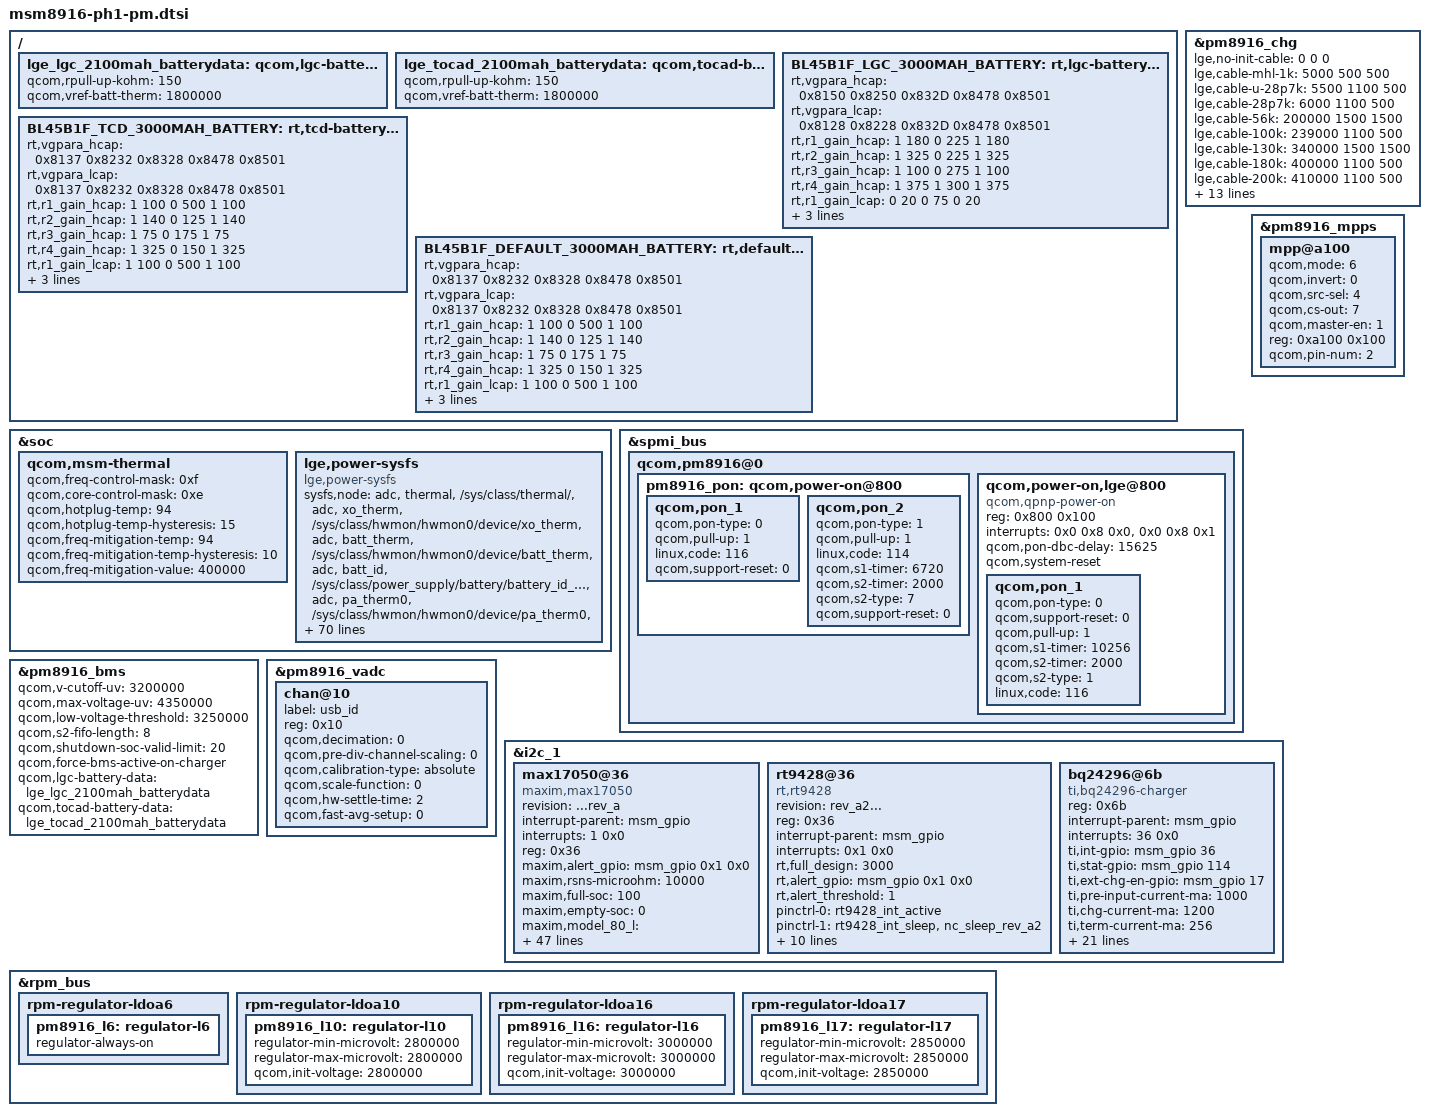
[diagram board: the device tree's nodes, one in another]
/* Copyright (c) 2012, Code Aurora Forum. All rights reserved.
 *
 * This program is free software; you can redistribute it and/or modify
* it under the terms of the GNU General Public License version 2 and
* only version 2 as published by the Free Software Foundation.
*
* This program is distributed in the hope that it will be useful,
* but WITHOUT ANY WARRANTY; without even the implied warranty of
* MERCHANTABILITY or FITNESS FOR A PARTICULAR PURPOSE.  See the
* GNU General Public License for more details.
*/

&pm8916_chg {
	status = "ok";

	lge,no-init-cable = <0 0 0>;
	lge,cable-mhl-1k = <5000 500 500>;
	lge,cable-u-28p7k = <5500 1100 500>;
	lge,cable-28p7k = <6000 1100 500>;
	lge,cable-56k = <200000 1500 1500>;
	lge,cable-100k = <239000 1100 500>;
	lge,cable-130k = <340000 1500 1500>;
	lge,cable-180k = <400000 1100 500>;
	lge,cable-200k = <410000 1100 500>;
	lge,cable-220k = <485000 1100 500>;
	lge,cable-270k = <560000 1100 500>;
	lge,cable-330k = <735000 1100 500>;
	lge,cable-620k = <955000 1100 500>;
	lge,cable-910k = <1140000 1500 1500>;
	lge,cable-none = <1900000 1100  500>;

	qcom,vddmax-mv = <4350>;
	qcom,vddsafe-mv = <4380>;
	qcom,vinmin-mv = <4470>;
	qcom,tchg-mins = <480>;
	qcom,btc-disabled;
	qcom,resume-soc = <98>;
	qcom,disable-vbatdet-based-recharge;
};

&soc {
	qcom,msm-thermal {
		qcom,freq-control-mask = <0xf>;
		qcom,core-control-mask = <0xe>;
		qcom,hotplug-temp = <94>;
		qcom,hotplug-temp-hysteresis = <15>;
		qcom,freq-mitigation-temp = <94>;
		qcom,freq-mitigation-temp-hysteresis = <10>;
		qcom,freq-mitigation-value = <400000>;
		};
};

&spmi_bus {
qcom,pm8916@0 {
		pm8916_pon: qcom,power-on@800 {
			status = "ok";
			qcom,pon_1 {
				qcom,pon-type = <0>;
				qcom,pull-up = <1>;
				linux,code = <116>;
				qcom,support-reset = <0>;
			};
			qcom,pon_2 {
				qcom,pon-type = <1>;
				qcom,pull-up = <1>;
				linux,code = <114>;
				qcom,s1-timer = <6720>;
				qcom,s2-timer = <2000>;
				qcom,s2-type = <7>;
				status = "ok";
				qcom,support-reset = <0>;
			};
		};
		qcom,power-on,lge@800 {
			compatible = "qcom,qpnp-power-on";
			reg = <0x800 0x100>;
			interrupts = <0x0 0x8 0x0>,
				     <0x0 0x8 0x1>;
			interrupt-names = "kpdpwr", "resin";
			qcom,pon-dbc-delay = <15625>;
			qcom,system-reset;
			status = "okay";
			qcom,pon_1 {
				qcom,pon-type = <0>;
				qcom,support-reset = <0>;
				qcom,pull-up = <1>;
				qcom,s1-timer = <10256>;
				qcom,s2-timer = <2000>;
				qcom,s2-type = <1>;
				linux,code = <116>;
			};
		};
	};
};

&pm8916_mpps {
	mpp@a100 {
		status = "okay";
		qcom,mode = <6>;
		qcom,invert = <0>;
		qcom,src-sel = <4>;
		qcom,cs-out = <7>;
		qcom,master-en = <1>;
		reg = <0xa100 0x100>;
		qcom,pin-num = <2>;
	};
};

/ {
	lge_lgc_2100mah_batterydata: qcom,lgc-battery-data {
		qcom,rpull-up-kohm = <150>;
		qcom,vref-batt-therm = <1800000>;

		#include "../msm8916-lge-common/batterydata_LGE_lgc_2100mAh.dtsi"
	};

	lge_tocad_2100mah_batterydata: qcom,tocad-battery-data {
		qcom,rpull-up-kohm = <150>;
		qcom,vref-batt-therm = <1800000>;

		#include "../msm8916-lge-common/batterydata_LGE_tocad_2100mAh.dtsi"
	};
};

/ {
	BL45B1F_LGC_3000MAH_BATTERY: rt,lgc-battery-data {
		rt,vgpara_hcap = <0x8150 0x8250 0x832D 0x8478 0x8501>;
		rt,vgpara_lcap = <0x8128 0x8228 0x832D 0x8478 0x8501>;
		rt,r1_gain_hcap = < 1 180 0 225 1 180>;
		rt,r2_gain_hcap = < 1 325 0 225 1 325>;
		rt,r3_gain_hcap = < 1 100 0 275 1 100>;
		rt,r4_gain_hcap = < 1 375 1 300 1 375>;
		rt,r1_gain_lcap = < 0 20 0 75 0 20>;
		rt,r2_gain_lcap = < 1 125 0 100 1 125>;
		rt,r3_gain_lcap = < 1 100 0 325 1 100>;
		rt,r4_gain_lcap = < 1 375 1 300 1 375>;
	};

        BL45B1F_TCD_3000MAH_BATTERY: rt,tcd-battery-data {
		rt,vgpara_hcap = <0x8137 0x8232 0x8328 0x8478 0x8501>;
		rt,vgpara_lcap = <0x8137 0x8232 0x8328 0x8478 0x8501>;
		rt,r1_gain_hcap = < 1 100 0 500 1 100>;
		rt,r2_gain_hcap = < 1 140 0 125 1 140>;
		rt,r3_gain_hcap = < 1 75 0 175 1 75>;
		rt,r4_gain_hcap = < 1 325 0 150 1 325>;
		rt,r1_gain_lcap = < 1 100 0 500 1 100>;
		rt,r2_gain_lcap = < 1 140 0 125 1 140>;
		rt,r3_gain_lcap = < 1 75 0 175 1 75>;
		rt,r4_gain_lcap = < 1 325 0 150 1 325>;
	};

	BL45B1F_DEFAULT_3000MAH_BATTERY: rt,default-battery-data {
		rt,vgpara_hcap = <0x8137 0x8232 0x8328 0x8478 0x8501>;
		rt,vgpara_lcap = <0x8137 0x8232 0x8328 0x8478 0x8501>;
		rt,r1_gain_hcap = < 1 100 0 500 1 100>;
		rt,r2_gain_hcap = < 1 140 0 125 1 140>;
		rt,r3_gain_hcap = < 1 75 0 175 1 75>;
		rt,r4_gain_hcap = < 1 325 0 150 1 325>;
		rt,r1_gain_lcap = < 1 100 0 500 1 100>;
		rt,r2_gain_lcap = < 1 140 0 125 1 140>;
		rt,r3_gain_lcap = < 1 75 0 175 1 75>;
		rt,r4_gain_lcap = < 1 325 0 150 1 325>;

	};
};

&pm8916_bms {
	status = "ok";
	qcom,v-cutoff-uv = <3200000>;
	qcom,max-voltage-uv = <4350000>;
	qcom,low-voltage-threshold = <3250000>;
	qcom,s2-fifo-length = <8>;
	qcom,shutdown-soc-valid-limit = <20>;
	qcom,force-bms-active-on-charger;
	qcom,lgc-battery-data = <&lge_lgc_2100mah_batterydata>;
	qcom,tocad-battery-data = <&lge_tocad_2100mah_batterydata>;
};

&pm8916_vadc {
	chan@10 {
		label = "usb_id";
		reg = <0x10>;
		qcom,decimation = <0>;
		qcom,pre-div-channel-scaling = <0>;
		qcom,calibration-type = "absolute";
		qcom,scale-function = <0>;
		qcom,hw-settle-time = <2>;
		qcom,fast-avg-setup = <0>;
	};
};

&i2c_1 {
	max17050@36 {
		revision = "...rev_a";
		compatible = "maxim,max17050";
		status = "ok";
		interrupt-parent = <&msm_gpio>;
		interrupts = <1 0x0>;
		reg = <0x36>;
		maxim,alert_gpio = <&msm_gpio 0x1 0x0>;

		maxim,rsns-microohm = <10000>;

		maxim,full-soc = <100>;
		maxim,empty-soc = <0>;

		/* LGC cell */
		maxim,model_80_l = [C0 9F 40 AB 20 B6 A0 B9
				80 BA 20 BC 10 BD D0 BD
				E0 BF 00 C2 F0 C4 10 C7
				40 C9 C0 CC 30 D2 50 D8];
		maxim,model_90_l = [20 00 60 02 20 0D 10 08
				00 13 70 1D 50 20 90 13
				B0 0B B0 09 E0 07 F0 0B
				E0 06 E0 07 F0 05 F0 05];
		maxim,model_A0_l = [00 01 00 01 00 01 00 01
				00 01 00 01 00 01 00 01
				00 01 00 01 00 01 00 01
				00 01 00 01 00 01 00 01];

		maxim,iavg_empty_l = <0x0C8A>;
		maxim,rcomp0_l = <0x0059>;
		maxim,tempco_l = <0x263A>;
		maxim,ichgterm_l = <0x0320>;
		maxim,vempty_l = <0xA05F>;
		maxim,qrtable00_l = <0x3200>;
		maxim,qrtable10_l = <0x1780>;
		maxim,qrtable20_l = <0x0A01>;
		maxim,qrtable30_l = <0x0681>;
		maxim,capacity_l = <0x0FAD>;
		maxim,vf_fullcap_l = <0x0FAD>;

		maxim,rescale_factor_l = <0>;

		/* Sanyo cell */
		maxim,model_80_d = [D0 9B 10 AB 40 B7 D0 B8
				00 BB 10 BC 30 BD 80 BE
				00 C0 50 C3 50 C5 90 C7
				60 C9 90 CD C0 CF B0 D6];
		maxim,model_90_d = [80 00 10 02 60 13 00 09
				00 1B 10 18 00 22 C0 10
				A0 0B D0 07 F0 0A D0 08
				E0 07 E0 08 F0 05 F0 05];
		maxim,model_A0_d = [00 02 00 02 00 02 00 02
				00 02 00 02 00 02 00 02
				00 02 00 02 00 02 00 02
				00 02 00 02 00 02 00 02];

		maxim,iavg_empty_d = <0x0C8F>;
		maxim,rcomp0_d = <0x0035>;
		maxim,tempco_d = <0x2E38>;
		maxim,ichgterm_d = <0x0320>;
		maxim,vempty_d = <0xA05F>;
		maxim,qrtable00_d = <0x4A00>;
		maxim,qrtable10_d = <0x1F80>;
		maxim,qrtable20_d = <0x0A05>;
		maxim,qrtable30_d = <0x0785>;
		maxim,capacity_d = <0x0FBC>;
		maxim,vf_fullcap_d = <0x0FBC>;

		maxim,rescale_factor_d = <2>;

		/* Common */
		maxim,config = <0x2104>;
		maxim,relaxcfg = <0x506B>;
		maxim,filtercfg = <0x87A4>;
		maxim,learncfg = <0x2606>;
		maxim,misccfg = <0x0870>;
		maxim,fullsocthr = <0x5F00>;
		maxim,tempnom = <0x1400>;
		maxim,tgain = <0xE932>;
		maxim,toff = <0x2381>;

		maxim,rescale_soc = <9300>;

		maxim,param-version = <0x1>;
		maxim,full_design = <2100>;
	};

	rt9428@36 {
		revision = "rev_a2...";
		compatible = "rt,rt9428";
		status = "ok";
		reg = <0x36>;
		interrupt-parent = <&msm_gpio>;
		interrupts = <0x1 0x0>;
		rt,full_design= <3000>;
		rt,alert_gpio = <&msm_gpio 0x1 0x0>;
		rt,alert_threshold = <1>;
		/* Pins config setting */
		pinctrl-names = "default", "sleep";
		pinctrl-0 = <&rt9428_int_active>;
		pinctrl-1 = <&rt9428_int_sleep &nc_sleep_rev_a2>;
		rt,soc_comp = <0>;
		rt,vgcomp0 = <0xAB>;
		rt,temp_base = <5 5 25 45>;
		rt,low_cut_off_gain = <5>;
		rt,lgc-battery-data = <&BL45B1F_LGC_3000MAH_BATTERY>;
		rt,tocad-battery-data = <&BL45B1F_TCD_3000MAH_BATTERY>;
		rt,default-battery-data = <&BL45B1F_DEFAULT_3000MAH_BATTERY>;
	};


	bq24296@6b {
		status = "ok";
		compatible = "ti,bq24296-charger";
		reg = <0x6b>;
		interrupt-parent = <&msm_gpio>;
		interrupts = <36 0x0>;
		ti,int-gpio = <&msm_gpio 36 0>;
		ti,stat-gpio = <&msm_gpio 114 0>;
		ti,ext-chg-en-gpio = <&msm_gpio 17 0>;
		ti,pre-input-current-ma = <1000>;
		ti,chg-current-ma = <1200>;
		ti,term-current-ma = <256>;
		ti,vbat-max-mv = <4368>;
		ti,pre-chg-current-ma = <512>;
		ti,sys-vmin-mv = <3600>;
		ti,vin-limit-mv = <4520>;
		ti,icl-vbus-mv = <4400>;

		lge,no-init-cable = <0 0 0>;
		lge,cable-mhl-1k = <5000 500 500>;
		lge,cable-u-28p7k = <5500 1500 500>;
		lge,cable-28p7k = <6000 1200 500>;
		lge,cable-56k = <178000 1500 1500>;
		lge,cable-100k = <178500 2000 500>;
		lge,cable-130k = <340000 500 500>;
		lge,cable-180k = <400000 1500 500>;
		lge,cable-200k = <410000 1500 500>;
		lge,cable-220k = <485000 1500 500>;
		lge,cable-270k = <560000 1500 500>;
		lge,cable-330k = <735000 1500 500>;
		lge,cable-620k = <955000 1500 500>;
		lge,cable-910k = <1200000 1500 1500>;
		lge,cable-none = <1900000 1500	500>;

		qcom,bq24296-vadc = <&pm8916_vadc>;
	};
};

&rpm_bus {
	rpm-regulator-ldoa6 {
		status = "okay";
		pm8916_l6: regulator-l6 {
			regulator-always-on;
			status = "okay";
		};
	};

	rpm-regulator-ldoa10 {
		status = "okay";
		pm8916_l10: regulator-l10 {
			regulator-min-microvolt = <2800000>;
			regulator-max-microvolt = <2800000>;
			qcom,init-voltage = <2800000>;
			//regulator-always-on;
			status = "okay";
		};
	};

	rpm-regulator-ldoa16 {
		status = "okay";
		pm8916_l16: regulator-l16 {
			regulator-min-microvolt = <3000000>;
			regulator-max-microvolt = <3000000>;
			qcom,init-voltage = <3000000>;
		//	regulator-always-on;
			status = "okay";
		};
	};

	rpm-regulator-ldoa17 {
		status = "okay";
		pm8916_l17: regulator-l17 {
			regulator-min-microvolt = <2850000>;
			regulator-max-microvolt = <2850000>;
			qcom,init-voltage = <2850000>;
			//regulator-always-on;
			status = "okay";
		};
	};
};

&soc {
	lge,power-sysfs {
		compatible = "lge,power-sysfs";

		sysfs,node =
			/* group , user_node,  kernel node */
			/* ADC/MPP */
			"adc", "thermal", "/sys/class/thermal/",
			"adc", "xo_therm", "/sys/class/hwmon/hwmon0/device/xo_therm",
			"adc", "batt_therm", "/sys/class/hwmon/hwmon0/device/batt_therm",
			"adc", "batt_id", "/sys/class/power_supply/battery/battery_id_checker",
			"adc", "pa_therm0", "/sys/class/hwmon/hwmon0/device/pa_therm0",
			"adc", "pa_therm1", "NULL",
			"adc", "usb_in", "/sys/class/hwmon/hwmon0/device/usb_in",
			"adc", "vcoin", "/sys/class/hwmon/hwmon0/device/vcoin",
			"adc", "vph_pwr", "/sys/class/hwmon/hwmon0/device/vph_pwr",
			"adc", "usb_id", "/sys/class/hwmon/hwmon0/device/usb_id",
			/* Battery */
			"battery", "capacity", "/sys/class/power_supply/battery/capacity",
			"battery", "health", "/sys/class/power_supply/battery/health",
			"battery", "present", "/sys/class/power_supply/battery/present",
			"battery", "pseudo_batt", "/sys/class/power_supply/battery/pseudo_batt",
			"battery", "status", "/sys/class/power_supply/battery/status",
			"battery", "temp", "/sys/class/power_supply/battery/temp",
			"battery", "valid_batt_id", "/sys/class/power_supply/battery/valid_batt_id",
			"battery", "voltage_now", "/sys/class/power_supply/battery/voltage_now",
			/* Charger */
			"charger", "ac_online", "NULL",
			"charger", "usb_online", "/sys/class/power_supply/usb/online",
			"charger", "present", "/sys/class/power_supply/usb/present",
			"charger", "wlc_online", "NULL",
			"charger", "type", "/sys/class/power_supply/usb/type",
			"charger", "time_out", "NULL",
			"charger", "charging_enabled", "/sys/class/power_supply/battery/charging_enabled",
			"charger", "ibat_current", "/sys/class/power_supply/battery/current_now",
			"charger", "ichg_current", "/sys/class/power_supply/usb/current_max",
			"charger", "iusb_control", "NULL",
			"charger", "thermal_mitigation", "/sys/module/bq24262_charger/parameters/bq24262_thermal_mitigation",
			"charger", "wlc_thermal_mitigation", "NULL",
			"charger", "usb_parallel_chg_status", "NULL",
			"charger", "usb_parallel_charging_enabled", "NULL",
			/* LCD Backlight */
			"lcd", "brightness", "/sys/class/leds/lcd-backlight/brightness",
			"lcd", "max_brightness", "/sys/class/leds/lcd-backlight/max_brightness",
			/* KEY LED */
			"key_led", "red_brightness", "/sys/class/leds/red/brightness",
			"key_led", "green_brightness", "NULL",
			"key_led", "blue_brightness", "NULL",
			/* CPU */
			"cpu", "cpu_idle_modes", "NULL",
			/* GPU */
			"gpu", "busy", "/sys/class/kgsl/kgsl-3d0/gpubusy",
			/* PLATFORM */
			"platform", "speed_bin", "NULL",
			"platform", "pvs_bin", "NULL",
			"platform", "power_state", "/sys/power/autosleep",
			"platform", "poweron_alarm", "/sys/module/qpnp_rtc/parameters/poweron_alarm",
			"platform", "pcb_rev", "/sys/class/power_supply/battery/hw_rev",
			/* testmode */
			"testmode", "charge", "/sys/class/power_supply/battery/device/at_charge",
			"testmode", "chcomp", "/sys/class/power_supply/battery/device/at_chcomp1",
			"testmode", "chgmodeoff", "/sys/class/power_supply/battery/charging_enabled",
			"testmode", "fuelrst", "NULL",
			"testmode", "rtc_time", "/dev/rtc0",
			"testmode", "pmrst", "NULL",
			"testmode", "battexit", "/sys/class/power_supply/battery/present",
			"testmode", "hw_rev", "/sys/class/power_supply/battery/hw_rev"
			;
	};
};
